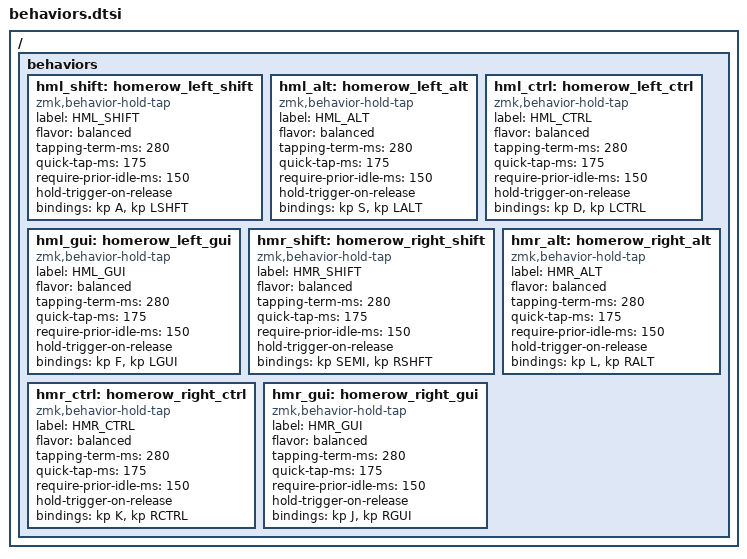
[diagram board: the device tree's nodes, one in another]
/ {
    behaviors {
        /*
         * Home-row mods cho layout kiểu QWERTY
         * Left hand : A S D F
         * Right hand: J K L ;
         *
         * Quy ước:
         *  - Tap  = ký tự
         *  - Hold = modifier
         */

        /* ========= LEFT HAND ========= */

        hml_shift: homerow_left_shift {
            compatible = "zmk,behavior-hold-tap";
            label = "HML_SHIFT";
            #binding-cells = <2>;

            flavor = "balanced";
            tapping-term-ms = <280>;
            quick-tap-ms = <175>;
            require-prior-idle-ms = <150>;
            hold-trigger-on-release;

            bindings = <&kp A &kp LSHFT>;
        };

        hml_alt: homerow_left_alt {
            compatible = "zmk,behavior-hold-tap";
            label = "HML_ALT";
            #binding-cells = <2>;

            flavor = "balanced";
            tapping-term-ms = <280>;
            quick-tap-ms = <175>;
            require-prior-idle-ms = <150>;
            hold-trigger-on-release;

            bindings = <&kp S &kp LALT>;
        };

        hml_ctrl: homerow_left_ctrl {
            compatible = "zmk,behavior-hold-tap";
            label = "HML_CTRL";
            #binding-cells = <2>;

            flavor = "balanced";
            tapping-term-ms = <280>;
            quick-tap-ms = <175>;
            require-prior-idle-ms = <150>;
            hold-trigger-on-release;

            bindings = <&kp D &kp LCTRL>;
        };

        hml_gui: homerow_left_gui {
            compatible = "zmk,behavior-hold-tap";
            label = "HML_GUI";
            #binding-cells = <2>;

            flavor = "balanced";
            tapping-term-ms = <280>;
            quick-tap-ms = <175>;
            require-prior-idle-ms = <150>;
            hold-trigger-on-release;

            bindings = <&kp F &kp LGUI>;
        };

        /* ========= RIGHT HAND ========= */

        hmr_shift: homerow_right_shift {
            compatible = "zmk,behavior-hold-tap";
            label = "HMR_SHIFT";
            #binding-cells = <2>;

            flavor = "balanced";
            tapping-term-ms = <280>;
            quick-tap-ms = <175>;
            require-prior-idle-ms = <150>;
            hold-trigger-on-release;

            bindings = <&kp SEMI &kp RSHFT>;
        };

        hmr_alt: homerow_right_alt {
            compatible = "zmk,behavior-hold-tap";
            label = "HMR_ALT";
            #binding-cells = <2>;

            flavor = "balanced";
            tapping-term-ms = <280>;
            quick-tap-ms = <175>;
            require-prior-idle-ms = <150>;
            hold-trigger-on-release;

            bindings = <&kp L &kp RALT>;
        };

        hmr_ctrl: homerow_right_ctrl {
            compatible = "zmk,behavior-hold-tap";
            label = "HMR_CTRL";
            #binding-cells = <2>;

            flavor = "balanced";
            tapping-term-ms = <280>;
            quick-tap-ms = <175>;
            require-prior-idle-ms = <150>;
            hold-trigger-on-release;

            bindings = <&kp K &kp RCTRL>;
        };

        hmr_gui: homerow_right_gui {
            compatible = "zmk,behavior-hold-tap";
            label = "HMR_GUI";
            #binding-cells = <2>;

            flavor = "balanced";
            tapping-term-ms = <280>;
            quick-tap-ms = <175>;
            require-prior-idle-ms = <150>;
            hold-trigger-on-release;

            bindings = <&kp J &kp RGUI>;
        };
    };
};
